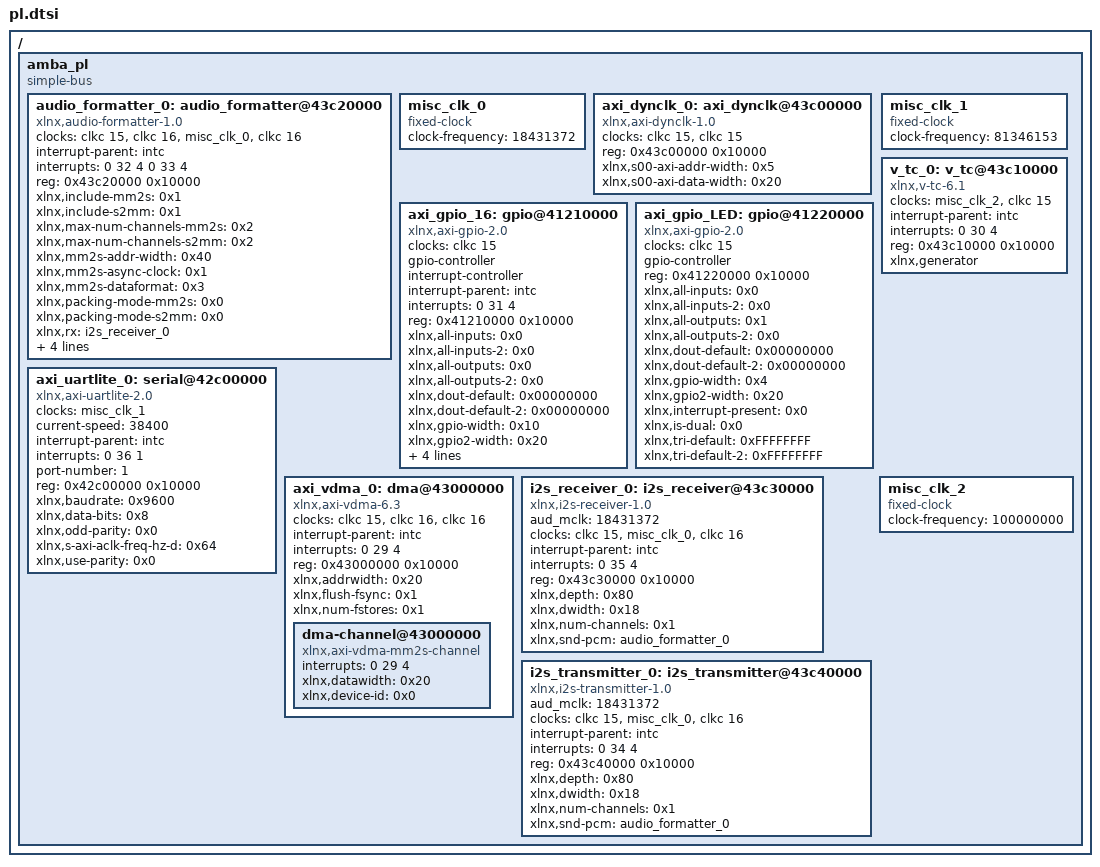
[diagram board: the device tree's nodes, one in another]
/*
 * CAUTION: This file is automatically generated by Xilinx.
 * Version: XSCT 2018.3
 * Today is: Thu Jul 31 20:00:34 2025
 */


/ {
	amba_pl: amba_pl {
		#address-cells = <1>;
		#size-cells = <1>;
		compatible = "simple-bus";
		ranges ;
		audio_formatter_0: audio_formatter@43c20000 {
			clock-names = "s_axi_lite_aclk", "m_axis_mm2s_aclk", "aud_mclk", "s_axis_s2mm_aclk";
			clocks = <&clkc 15>, <&clkc 16>, <&misc_clk_0>, <&clkc 16>;
			compatible = "xlnx,audio-formatter-1.0", "xlnx,audio-formatter-1.0";
			interrupt-names = "irq_mm2s", "irq_s2mm";
			interrupt-parent = <&intc>;
			interrupts = <0 32 4 0 33 4>;
			reg = <0x43c20000 0x10000>;
			xlnx,include-mm2s = <0x1>;
			xlnx,include-s2mm = <0x1>;
			xlnx,max-num-channels-mm2s = <0x2>;
			xlnx,max-num-channels-s2mm = <0x2>;
			xlnx,mm2s-addr-width = <0x40>;
			xlnx,mm2s-async-clock = <0x1>;
			xlnx,mm2s-dataformat = <0x3>;
			xlnx,packing-mode-mm2s = <0x0>;
			xlnx,packing-mode-s2mm = <0x0>;
			xlnx,rx = <&i2s_receiver_0>;
			xlnx,s2mm-addr-width = <0x40>;
			xlnx,s2mm-async-clock = <0x1>;
			xlnx,s2mm-dataformat = <0x1>;
			xlnx,tx = <&i2s_transmitter_0>;
		};
		misc_clk_0: misc_clk_0 {
			#clock-cells = <0>;
			clock-frequency = <18431372>;
			compatible = "fixed-clock";
		};
		axi_dynclk_0: axi_dynclk@43c00000 {
			/* This is a place holder node for a custom IP, user may need to update the entries */
			clock-names = "REF_CLK_I", "s00_axi_aclk";
			clocks = <&clkc 15>, <&clkc 15>;
			compatible = "xlnx,axi-dynclk-1.0";
			reg = <0x43c00000 0x10000>;
			xlnx,s00-axi-addr-width = <0x5>;
			xlnx,s00-axi-data-width = <0x20>;
		};
		axi_gpio_16: gpio@41210000 {
			#gpio-cells = <2>;
			#interrupt-cells = <2>;
			clock-names = "s_axi_aclk";
			clocks = <&clkc 15>;
			compatible = "xlnx,axi-gpio-2.0", "xlnx,xps-gpio-1.00.a";
			gpio-controller ;
			interrupt-controller ;
			interrupt-names = "ip2intc_irpt";
			interrupt-parent = <&intc>;
			interrupts = <0 31 4>;
			reg = <0x41210000 0x10000>;
			xlnx,all-inputs = <0x0>;
			xlnx,all-inputs-2 = <0x0>;
			xlnx,all-outputs = <0x0>;
			xlnx,all-outputs-2 = <0x0>;
			xlnx,dout-default = <0x00000000>;
			xlnx,dout-default-2 = <0x00000000>;
			xlnx,gpio-width = <0x10>;
			xlnx,gpio2-width = <0x20>;
			xlnx,interrupt-present = <0x1>;
			xlnx,is-dual = <0x0>;
			xlnx,tri-default = <0xFFFFFFFF>;
			xlnx,tri-default-2 = <0xFFFFFFFF>;
		};
		axi_gpio_LED: gpio@41220000 {
			#gpio-cells = <2>;
			clock-names = "s_axi_aclk";
			clocks = <&clkc 15>;
			compatible = "xlnx,axi-gpio-2.0", "xlnx,xps-gpio-1.00.a";
			gpio-controller ;
			reg = <0x41220000 0x10000>;
			xlnx,all-inputs = <0x0>;
			xlnx,all-inputs-2 = <0x0>;
			xlnx,all-outputs = <0x1>;
			xlnx,all-outputs-2 = <0x0>;
			xlnx,dout-default = <0x00000000>;
			xlnx,dout-default-2 = <0x00000000>;
			xlnx,gpio-width = <0x4>;
			xlnx,gpio2-width = <0x20>;
			xlnx,interrupt-present = <0x0>;
			xlnx,is-dual = <0x0>;
			xlnx,tri-default = <0xFFFFFFFF>;
			xlnx,tri-default-2 = <0xFFFFFFFF>;
		};
		axi_uartlite_0: serial@42c00000 {
			clock-names = "s_axi_aclk";
			clocks = <&misc_clk_1>;
			compatible = "xlnx,axi-uartlite-2.0", "xlnx,xps-uartlite-1.00.a";
			current-speed = <38400>;
			device_type = "serial";
			interrupt-names = "interrupt";
			interrupt-parent = <&intc>;
			interrupts = <0 36 1>;
			port-number = <1>;
			reg = <0x42c00000 0x10000>;
			xlnx,baudrate = <0x9600>;
			xlnx,data-bits = <0x8>;
			xlnx,odd-parity = <0x0>;
			xlnx,s-axi-aclk-freq-hz-d = <0x64>;
			xlnx,use-parity = <0x0>;
		};
		misc_clk_1: misc_clk_1 {
			#clock-cells = <0>;
			clock-frequency = <81346153>;
			compatible = "fixed-clock";
		};
		axi_vdma_0: dma@43000000 {
			#dma-cells = <1>;
			clock-names = "s_axi_lite_aclk", "m_axi_mm2s_aclk", "m_axis_mm2s_aclk";
			clocks = <&clkc 15>, <&clkc 16>, <&clkc 16>;
			compatible = "xlnx,axi-vdma-6.3", "xlnx,axi-vdma-1.00.a";
			interrupt-names = "mm2s_introut";
			interrupt-parent = <&intc>;
			interrupts = <0 29 4>;
			reg = <0x43000000 0x10000>;
			xlnx,addrwidth = <0x20>;
			xlnx,flush-fsync = <0x1>;
			xlnx,num-fstores = <0x1>;
			dma-channel@43000000 {
				compatible = "xlnx,axi-vdma-mm2s-channel";
				interrupts = <0 29 4>;
				xlnx,datawidth = <0x20>;
				xlnx,device-id = <0x0>;
			};
		};
		i2s_receiver_0: i2s_receiver@43c30000 {
			aud_mclk = <18431372>;
			clock-names = "s_axi_ctrl_aclk", "aud_mclk", "m_axis_aud_aclk";
			clocks = <&clkc 15>, <&misc_clk_0>, <&clkc 16>;
			compatible = "xlnx,i2s-receiver-1.0", "xlnx,i2s-receiver-1.0";
			interrupt-names = "irq";
			interrupt-parent = <&intc>;
			interrupts = <0 35 4>;
			reg = <0x43c30000 0x10000>;
			xlnx,depth = <0x80>;
			xlnx,dwidth = <0x18>;
			xlnx,num-channels = <0x1>;
			xlnx,snd-pcm = <&audio_formatter_0>;
		};
		i2s_transmitter_0: i2s_transmitter@43c40000 {
			aud_mclk = <18431372>;
			clock-names = "s_axi_ctrl_aclk", "aud_mclk", "s_axis_aud_aclk";
			clocks = <&clkc 15>, <&misc_clk_0>, <&clkc 16>;
			compatible = "xlnx,i2s-transmitter-1.0", "xlnx,i2s-transmitter-1.0";
			interrupt-names = "irq";
			interrupt-parent = <&intc>;
			interrupts = <0 34 4>;
			reg = <0x43c40000 0x10000>;
			xlnx,depth = <0x80>;
			xlnx,dwidth = <0x18>;
			xlnx,num-channels = <0x1>;
			xlnx,snd-pcm = <&audio_formatter_0>;
		};
		v_tc_0: v_tc@43c10000 {
			clock-names = "clk", "s_axi_aclk";
			clocks = <&misc_clk_2>, <&clkc 15>;
			compatible = "xlnx,v-tc-6.1", "xlnx,v-tc-6.1";
			interrupt-names = "irq";
			interrupt-parent = <&intc>;
			interrupts = <0 30 4>;
			reg = <0x43c10000 0x10000>;
			xlnx,generator ;
		};
		misc_clk_2: misc_clk_2 {
			#clock-cells = <0>;
			clock-frequency = <100000000>;
			compatible = "fixed-clock";
		};
	};
};
